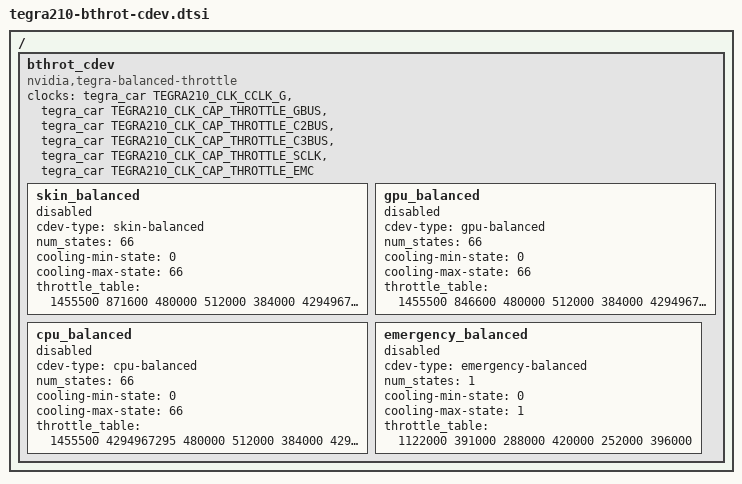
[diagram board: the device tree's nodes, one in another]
/*
 * arch/arm64/boot/dts/tegra210-platforms/tegra210-bthrot-cdev.dtsi
 *
 * Copyright (c) 2014 - 2017, NVIDIA CORPORATION.  All rights reserved.
 *
 * This program is free software; you can redistribute it and/or modify
 * it under the terms of the GNU General Public License as published by
 * the Free Software Foundation; version 2 of the License.
 *
 * This program is distributed in the hope that it will be useful, but WITHOUT
 * ANY WARRANTY; without even the implied warranty of MERCHANTABILITY or
 * FITNESS FOR A PARTICULAR PURPOSE.  See the GNU General Public License for
 * more details.
 *
 * You should have received a copy of the GNU General Public License along
 * with this program; if not, write to the Free Software Foundation, Inc.,
 * 51 Franklin Street, Fifth Floor, Boston, MA  02110-1301, USA.
 *
 */

/{
	bthrot_cdev {
		compatible = "nvidia,tegra-balanced-throttle";
		clocks = <&tegra_car TEGRA210_CLK_CCLK_G>,
				<&tegra_car TEGRA210_CLK_CAP_THROTTLE_GBUS>,
				<&tegra_car TEGRA210_CLK_CAP_THROTTLE_C2BUS>,
				<&tegra_car TEGRA210_CLK_CAP_THROTTLE_C3BUS>,
				<&tegra_car TEGRA210_CLK_CAP_THROTTLE_SCLK>,
				<&tegra_car TEGRA210_CLK_CAP_THROTTLE_EMC>;
		clock-names = "cclk_g", "gpu", "cap.throttle.c2bus",
				"cap.throttle.c3bus", "cap.throttle.sclk",
				"emc";
		skin_balanced {
			cdev-type = "skin-balanced";
			num_states = <66>;
			cooling-min-state = <0>;
			cooling-max-state = <66>;
			#cooling-cells = <2>;
			status = "disabled";
			throttle_table = <
			/*	CPU	GPU	C2BUS	C3BUS	SCLK	EMC	*/
				1455500	871600  480000	512000	384000	4294967295
				1436092	859295  480000	512000	384000	4294967295
				1416685	846991  480000	512000	384000	4294967295
				1397277	834686  480000	512000	384000	4294967295
				1377869	822382  480000	512000	384000	4294967295
				1358462	810077  480000	512000	384000	4294967295
				1339054	797772  480000	512000	384000	4294967295
				1319646	785468  480000	512000	384000	4294967295
				1300238	773163  480000	512000	384000	4294967295
				1280831	760858  480000	512000	384000	4294967295
				1261423	748554  480000	512000	384000	4294967295
				1242015	736249  480000	512000	384000	4294967295
				1222608	723945  480000	512000	384000	4294967295
				1203200	711640  480000	512000	384000	4294967295
				1183792	699335  480000	512000	384000	4294967295
				1164385	687031  480000	512000	384000	4294967295
				1144977	674726  480000	512000	384000	4294967295
				1125569	662422  480000	512000	384000	4294967295
				1106162	650117  480000	512000	384000	4294967295
				1086754	637812  480000	512000	384000	4294967295
				1067346	625508  480000	512000	384000	4294967295
				1047938	613203  480000	512000	384000	4294967295
				1028531	600898  480000	512000	384000	4294967295
				1009123	588594  480000	512000	384000	4294967295
				989715	576289  480000	512000	384000	4294967295
				970308	563985  480000	512000	384000	4294967295
				950900	551680  480000	512000	384000	4294967295
				931492	539375  480000	512000	384000	4294967295
				912085	527071  480000	512000	384000	4294967295
				892677	514766  480000	512000	384000	4294967295
				873269	502462  480000	512000	384000	4294967295
				853862	490157  480000	512000	384000	4294967295
				834454	477852  480000	512000	384000	4294967295
				815046	465548  480000	512000	384000	4294967295
				795638	453243  480000	512000	384000	4294967295
				776231	440938  480000	486400	384000	4294967295
				756823	428634  480000	486400	384000	4294967295
				737415	416329  480000	486400	384000	4294967295
				718008	404025  480000	486400	384000	4294967295
				698600	391720  480000	486400	384000	4294967295
				679192	379415  480000	486400	384000	4294967295
				659785	367111  480000	486400	384000	4294967295
				640377	354806  480000	486400	384000	4294967295
				620969	342502  480000	486400	384000	4294967295
				601562	330197  480000	473600	384000	4294967295
				582154	317892  480000	473600	384000	4294967295
				562746	305588  480000	473600	384000	4294967295
				543338	293283  480000	473600	384000	4294967295
				523931	280978  480000	473600	384000	4294967295
				504523	268674  480000	473600	384000	4294967295
				485115	256369  480000	473600	384000	4294967295
				465708	244065  480000	435200	384000	4294967295
				446300	231760  480000	435200	384000	4294967295
				426892	219455  480000	435200	384000	4294967295
				407485	207151  480000	435200	384000	4294967295
				388077	194846  480000	435200	384000	4294967295
				368669	182542  480000	435200	384000	4294967295
				349262	170237  480000	396800	384000	4294967295
				329854	157932  480000	396800	384000	4294967295
				310446	145628  480000	396800	384000	4294967295
				291038	133323  480000	396800	384000	4294967295
				271631	121018  480000	396800	384000	4294967295
				252223	108714  480000	396800	384000	4294967295
				232815	96409   480000	396800	384000	4294967295
				213408	84105   480000	396800	384000	4294967295
				194000	71800   480000	396800	384000	4294967295
			>;
		};
		gpu_balanced {
			cdev-type = "gpu-balanced";
			num_states = <66>;
			cooling-min-state = <0>;
			cooling-max-state = <66>;
			#cooling-cells = <2>;
			status = "disabled";
			throttle_table = <
			/*	CPU	GPU	C2BUS	C3BUS	SCLK	EMC	*/
				1455500	846600  480000	512000	384000	4294967295
				1436092	831408  480000	512000	384000	4294967295
				1416685	816216  480000	512000	384000	4294967295
				1397277	801024  480000	512000	384000	4294967295
				1377869	785831  480000	512000	384000	4294967295
				1358462	770639  480000	512000	384000	4294967295
				1339054	755447  480000	512000	384000	4294967295
				1319646	740255  480000	512000	384000	4294967295
				1300238	725063  480000	512000	384000	4294967295
				1280831	709871  480000	512000	384000	4294967295
				1261423	694678  480000	512000	384000	4294967295
				1242015	679486  480000	512000	384000	4294967295
				1222608	664294  480000	512000	384000	4294967295
				1203200	649102  480000	512000	384000	4294967295
				1183792	633910  480000	512000	384000	4294967295
				1164385	618718  480000	512000	384000	4294967295
				1144977	603525  480000	512000	384000	4294967295
				1125569	588333  480000	512000	384000	4294967295
				1106162	573141  480000	512000	384000	4294967295
				1086754	557949  480000	512000	384000	4294967295
				1067346	542757  480000	512000	384000	4294967295
				1047938	527565  480000	512000	384000	4294967295
				1028531	512373  480000	512000	384000	4294967295
				1009123	497180  480000	512000	384000	4294967295
				989715	481988  480000	512000	384000	4294967295
				970308	466796  480000	512000	384000	4294967295
				950900	451604  480000	512000	384000	4294967295
				931492	436412  480000	512000	384000	4294967295
				912085	421220  480000	512000	384000	4294967295
				892677	406027  480000	512000	384000	4294967295
				873269	390835  480000	512000	384000	4294967295
				853862	375643  480000	512000	384000	4294967295
				834454	360451  480000	512000	384000	4294967295
				815046	345259  480000	512000	384000	4294967295
				795638	330067  480000	512000	384000	4294967295
				776231	314875  480000	486400	384000	4294967295
				756823	299682  480000	486400	384000	4294967295
				737415	284490  480000	486400	384000	4294967295
				718008	269298  480000	486400	384000	4294967295
				698600	254106  480000	486400	384000	4294967295
				679192	238914  480000	486400	384000	4294967295
				659785	223722  480000	486400	384000	4294967295
				640377	208529  480000	486400	384000	4294967295
				620969	193337  480000	486400	384000	4294967295
				601562	178145  480000	473600	384000	4294967295
				582154	162953  480000	473600	384000	4294967295
				562746	147761  480000	473600	384000	4294967295
				543338	132569  480000	473600	384000	4294967295
				523931	117376  480000	473600	384000	4294967295
				504523	102184  480000	473600	384000	4294967295
				485115	86992   480000	473600	384000	4294967295
				465708	61800   480000	435200	384000	4294967295
			>;
		};
		cpu_balanced {
			cdev-type = "cpu-balanced";
			num_states = <66>;
			cooling-min-state = <0>;
			cooling-max-state = <66>;
			#cooling-cells = <2>;
			status = "disabled";
			throttle_table = <
			/*	CPU	GPU		C2BUS	C3BUS	SCLK	EMC	*/
				1455500	4294967295      480000	512000	384000	4294967295
				1436092	4294967295      480000	512000	384000	4294967295
				1416685	4294967295      480000	512000	384000	4294967295
				1397277	4294967295      480000	512000	384000	4294967295
				1377869	4294967295      480000	512000	384000	4294967295
				1358462	4294967295      480000	512000	384000	4294967295
				1339054	4294967295      480000	512000	384000	4294967295
				1319646	4294967295      480000	512000	384000	4294967295
				1300238	4294967295      480000	512000	384000	4294967295
				1280831	4294967295      480000	512000	384000	4294967295
				1261423	921600          480000	512000	384000	4294967295
				1242015	906149          480000	512000	384000	4294967295
				1222608	890698          480000	512000	384000	4294967295
				1203200	875247          480000	512000	384000	4294967295
				1183792	859796          480000	512000	384000	4294967295
				1164385	844345          480000	512000	384000	4294967295
				1144977	828895          480000	512000	384000	4294967295
				1125569	813444          480000	512000	384000	4294967295
				1106162	797993          480000	512000	384000	4294967295
				1086754	782542          480000	512000	384000	4294967295
				1067346	767091          480000	512000	384000	4294967295
				1047938	751640          480000	512000	384000	4294967295
				1028531	736189          480000	512000	384000	4294967295
				1009123	720738          480000	512000	384000	4294967295
				989715	705287          480000	512000	384000	4294967295
				970308	689836          480000	512000	384000	4294967295
				950900	674385          480000	512000	384000	4294967295
				931492	658935          480000	512000	384000	4294967295
				912085	643484          480000	512000	384000	4294967295
				892677	628033          480000	512000	384000	4294967295
				873269	612582          480000	512000	384000	4294967295
				853862	597131          480000	512000	384000	4294967295
				834454	581680          480000	512000	384000	4294967295
				815046	566229          480000	512000	384000	4294967295
				795638	550778          480000	512000	384000	4294967295
				776231	535327          480000	486400	384000	4294967295
				756823	519876          480000	486400	384000	4294967295
				737415	504425          480000	486400	384000	4294967295
				718008	488975          480000	486400	384000	4294967295
				698600	473524          480000	486400	384000	4294967295
				679192	458073          480000	486400	384000	4294967295
				659785	442622          480000	486400	384000	4294967295
				640377	427171          480000	486400	384000	4294967295
				620969	411720          480000	486400	384000	4294967295
				601562	396269          480000	473600	384000	4294967295
				582154	380818          480000	473600	384000	4294967295
				562746	365367          480000	473600	384000	4294967295
				543338	349916          480000	473600	384000	4294967295
				523931	334465          480000	473600	384000	4294967295
				504523	319015          480000	473600	384000	4294967295
				485115	303564          480000	473600	384000	4294967295
				465708	288113          480000	435200	384000	4294967295
				446300	272662          480000	435200	384000	4294967295
				426892	257211          480000	435200	384000	4294967295
				407485	241760          480000	435200	384000	4294967295
				388077	226309          480000	435200	384000	4294967295
				368669	210858          480000	435200	384000	4294967295
				349262	195407          480000	396800	384000	4294967295
				329854	179956          480000	396800	384000	4294967295
				310446	164505          480000	396800	384000	4294967295
				291038	149055          480000	396800	384000	4294967295
				271631	133604          480000	396800	384000	4294967295
				252223	118153          480000	396800	384000	4294967295
				232815	102702          480000	396800	384000	4294967295
				213408	87251           480000	396800	384000	4294967295
				194000	71800           480000	396800	384000	4294967295
			>;
		};
		emergency_balanced {
			cdev-type = "emergency-balanced";
			num_states = <1>;
			cooling-min-state = <0>;
			cooling-max-state = <1>;
			#cooling-cells = <2>;
			status = "disabled";
			throttle_table = <
				/*CPU		GPU		C2BUS		C3BUS		SCLK		EMC	*/
				1122000		391000		288000		420000		252000		396000
			>;
		};
	};
};
